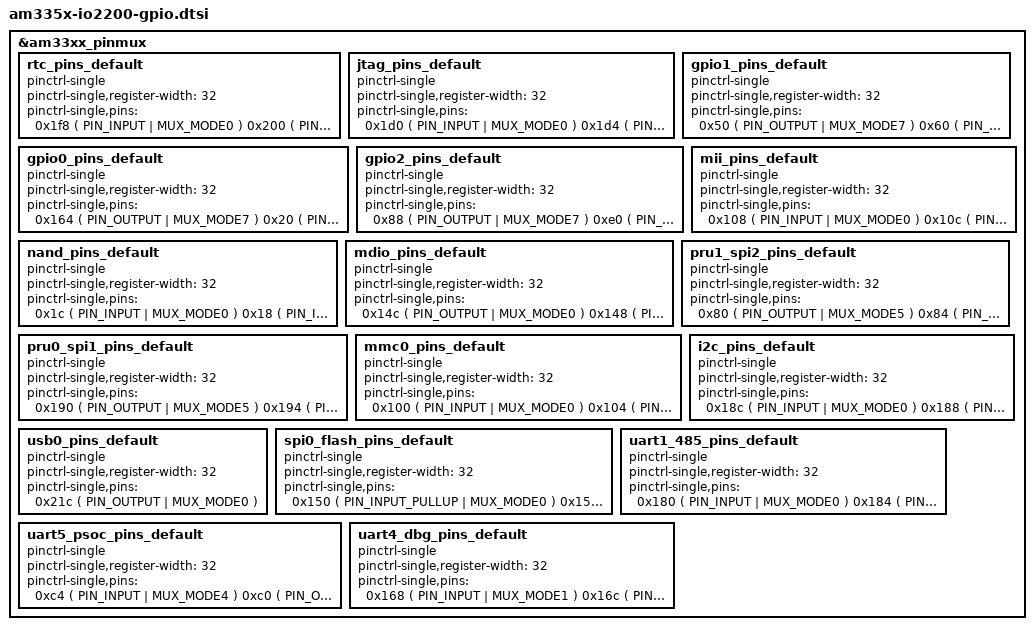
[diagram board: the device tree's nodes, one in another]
/* This file was auto-generated by TI PinMux on 10/19/2017 at 10:42:39 AM. */
/* This file should only be used as a reference.  Some pins/peripherals, */
/* depending on your use case, may need additional configuration. */

/* Some or all the pins from the following groups are not used by device tree 
   ddr
   32k765
   usb0
*/
&am33xx_pinmux {
rtc_pins_default: rtc_pins_default {
	compatible = "pinctrl-single";
	#pinctrl-cells = <1>;
	pinctrl-single,register-width = <32>;
	pinctrl-single,pins = <
		0x1f8 ( PIN_INPUT | MUX_MODE0 ) /* (B5) RTC_PORz.RTC_PORz */
		0x200 ( PIN_OUTPUT | MUX_MODE0 ) /* (C5) EXT_WAKEUP.EXT_WAKEUP */
		0x204 ( PIN_INPUT | MUX_MODE0 ) /* (B4) ENZ_KALDO_1P8V.ENZ_KALDO_1P8V */
	>;
};

jtag_pins_default: jtag_pins_default {
	compatible = "pinctrl-single";
	#pinctrl-cells = <1>;
	pinctrl-single,register-width = <32>;
	pinctrl-single,pins = <
		0x1d0 ( PIN_INPUT | MUX_MODE0 ) /* (C11) TMS.TMS */
		0x1d4 ( PIN_INPUT | MUX_MODE0 ) /* (B11) TDI.TDI */
		0x1d8 ( PIN_OUTPUT | MUX_MODE0 ) /* (A11) TDO.TDO */
		0x1dc ( PIN_INPUT | MUX_MODE0 ) /* (A12) TCK.TCK */
		0x1e0 ( PIN_INPUT | MUX_MODE0 ) /* (B10) nTRST.nTRST */
		0x1e4 ( PIN_INPUT | MUX_MODE0 ) /* (C14) EMU0.EMU0 */
		0x1e8 ( PIN_INPUT | MUX_MODE0 ) /* (B14) EMU1.EMU1 */
	>;
};

gpio1_pins_default: gpio1_pins_default {
	compatible = "pinctrl-single";
	#pinctrl-cells = <1>;
	pinctrl-single,register-width = <32>;
	pinctrl-single,pins = <
		0x50 ( PIN_OUTPUT | MUX_MODE7 ) /* (R14) gpmc_a4.gpio1[20] */
		0x60 ( PIN_OUTPUT | MUX_MODE7 ) /* (R14) gpmc_a8.gpio1[24] */
	>;
};

gpio0_pins_default: gpio0_pins_default {
	compatible = "pinctrl-single";
	#pinctrl-cells = <1>;
	pinctrl-single,register-width = <32>;
	pinctrl-single,pins = <
		0x164 ( PIN_OUTPUT | MUX_MODE7 ) /* (C18) eCAP0_in_PWM0_out.gpio0[7] */
		0x20 ( PIN_INPUT_PULLUP | MUX_MODE7 ) /* (U10) gpmc_ad8.gpio0[22] */
		0x24 ( PIN_INPUT_PULLDOWN | MUX_MODE7 ) /* (T10) gpmc_ad9.gpio0[23] */
		0x28 ( PIN_INPUT | MUX_MODE7 ) /* (T11) gpmc_ad10.gpio0[26] */
		0x2c ( PIN_INPUT | MUX_MODE7 ) /* (U12) gpmc_ad11.gpio0[27] */
		0x144 ( PIN_INPUT_PULLDOWN | MUX_MODE7 ) /* (H18) rmii1_refclk.gpio0[29] */
	>;
};

gpio2_pins_default: gpio2_pins_default {
	compatible = "pinctrl-single";
	#pinctrl-cells = <1>;
	pinctrl-single,register-width = <32>;
	pinctrl-single,pins = <
		0x88 ( PIN_OUTPUT | MUX_MODE7 ) /* (T13) gpmc_csn3.gpio2[0] */
		0xe0 ( PIN_OUTPUT | MUX_MODE7 ) /* (U5) lcd_vsync.gpio2[22] */
	>;
};

mii_pins_default: mii_pins_default {
	compatible = "pinctrl-single";
	#pinctrl-cells = <1>;
	pinctrl-single,register-width = <32>;
	pinctrl-single,pins = <
		0x108 ( PIN_INPUT | MUX_MODE0 ) /* (H16) gmii1_col.gmii1_col */
		0x10c ( PIN_INPUT | MUX_MODE0 ) /* (H17) gmii1_crs.gmii1_crs */
		0x110 ( PIN_INPUT_PULLDOWN | MUX_MODE0 ) /* (J15) gmii1_rxer.gmii1_rxer */
		0x114 ( PIN_OUTPUT | MUX_MODE0 ) /* (J16) gmii1_txen.gmii1_txen */
		0x118 ( PIN_INPUT | MUX_MODE0 ) /* (J17) gmii1_rxdv.gmii1_rxdv */
		0x12c ( PIN_INPUT | MUX_MODE0 ) /* (K18) gmii1_txclk.gmii1_txclk */
		0x130 ( PIN_INPUT | MUX_MODE0 ) /* (L18) gmii1_rxclk.gmii1_rxclk */
		0x128 ( PIN_OUTPUT | MUX_MODE0 ) /* (K17) gmii1_txd0.gmii1_txd0 */
		0x124 ( PIN_OUTPUT | MUX_MODE0 ) /* (K16) gmii1_txd1.gmii1_txd1 */
		0x120 ( PIN_OUTPUT | MUX_MODE0 ) /* (K15) gmii1_txd2.gmii1_txd2 */
		0x11c ( PIN_OUTPUT | MUX_MODE0 ) /* (J18) gmii1_txd3.gmii1_txd3 */
		0x140 ( PIN_INPUT | MUX_MODE0 ) /* (M16) gmii1_rxd0.gmii1_rxd0 */
		0x13c ( PIN_INPUT | MUX_MODE0 ) /* (L15) gmii1_rxd1.gmii1_rxd1 */
		0x138 ( PIN_INPUT | MUX_MODE0 ) /* (L16) gmii1_rxd2.gmii1_rxd2 */
		0x134 ( PIN_INPUT | MUX_MODE0 ) /* (L17) gmii1_rxd3.gmii1_rxd3 */
	>;
};

nand_pins_default: nand_pins_default {
	compatible = "pinctrl-single";
	#pinctrl-cells = <1>;
	pinctrl-single,register-width = <32>;
	pinctrl-single,pins = <
		0x1c ( PIN_INPUT | MUX_MODE0 ) /* (T9) gpmc_ad7.gpmc_ad7 */
		0x18 ( PIN_INPUT | MUX_MODE0 ) /* (R9) gpmc_ad6.gpmc_ad6 */
		0x14 ( PIN_INPUT | MUX_MODE0 ) /* (V8) gpmc_ad5.gpmc_ad5 */
		0x10 ( PIN_INPUT | MUX_MODE0 ) /* (U8) gpmc_ad4.gpmc_ad4 */
		0xc ( PIN_INPUT | MUX_MODE0 ) /* (T8) gpmc_ad3.gpmc_ad3 */
		0x8 ( PIN_INPUT | MUX_MODE0 ) /* (R8) gpmc_ad2.gpmc_ad2 */
		0x4 ( PIN_INPUT | MUX_MODE0 ) /* (V7) gpmc_ad1.gpmc_ad1 */
		0x0 ( PIN_INPUT | MUX_MODE0 ) /* (U7) gpmc_ad0.gpmc_ad0 */
		0x70 ( PIN_INPUT | MUX_MODE0 ) /* (T17) gpmc_wait0.gpmc_wait0 */
		0x74 ( PIN_OUTPUT | MUX_MODE0 ) /* (U17) gpmc_wpn.gpmc_wpn */
		0x90 ( PIN_OUTPUT | MUX_MODE0 ) /* (R7) gpmc_advn_ale.gpmc_advn_ale */
		0x94 ( PIN_OUTPUT | MUX_MODE0 ) /* (T7) gpmc_oen_ren.gpmc_oen_ren */
		0x98 ( PIN_OUTPUT | MUX_MODE0 ) /* (U6) gpmc_wen.gpmc_wen */
		0x9c ( PIN_OUTPUT | MUX_MODE0 ) /* (T6) gpmc_be0n_cle.gpmc_be0n_cle */
		0x7c ( PIN_OUTPUT | MUX_MODE0 ) /* (V6) gpmc_csn0.gpmc_csn0 */
	>;
};

mdio_pins_default: mdio_pins_default {
	compatible = "pinctrl-single";
	#pinctrl-cells = <1>;
	pinctrl-single,register-width = <32>;
	pinctrl-single,pins = <
		0x14c ( PIN_OUTPUT | MUX_MODE0 ) /* (M18) mdio_clk.mdio_clk */
		0x148 ( PIN_INPUT | MUX_MODE0 ) /* (M17) mdio_data.mdio_data */
	>;
};

pru1_spi2_pins_default: pru1_spi2_pins_default {
	compatible = "pinctrl-single";
	#pinctrl-cells = <1>;
	pinctrl-single,register-width = <32>;
	pinctrl-single,pins = <
		0x80 ( PIN_OUTPUT | MUX_MODE5 ) /* (U9) gpmc_csn1.pr1_pru1_pru_r30[12] */
		0x84 ( PIN_OUTPUT | MUX_MODE5 ) /* (V9) gpmc_csn2.pr1_pru1_pru_r30[13] */
		0x170 ( PIN_OUTPUT | MUX_MODE5 ) /* (E15) uart0_rxd.pr1_pru1_pru_r30[14] */
		0x174 ( PIN_INPUT | MUX_MODE6 ) /* (E16) uart0_txd.pr1_pru1_pru_r31[15] */
	>;
};

pru0_spi1_pins_default: pru0_spi1_pins_default {
	compatible = "pinctrl-single";
	#pinctrl-cells = <1>;
	pinctrl-single,register-width = <32>;
	pinctrl-single,pins = <
		0x190 ( PIN_OUTPUT | MUX_MODE5 ) /* (A13) mcasp0_aclkx.pr1_pru0_pru_r30[0] */
		0x194 ( PIN_OUTPUT | MUX_MODE5 ) /* (B13) mcasp0_fsx.pr1_pru0_pru_r30[1] */
		0x198 ( PIN_OUTPUT | MUX_MODE5 ) /* (D12) mcasp0_axr0.pr1_pru0_pru_r30[2] */
		0x19c ( PIN_OUTPUT | MUX_MODE5 ) /* (C12) mcasp0_ahclkr.pr1_pru0_pru_r30[3] */
		0x1a0 ( PIN_OUTPUT | MUX_MODE5 ) /* (B12) mcasp0_aclkr.pr1_pru0_pru_r30[4] */
		0x1a4 ( PIN_OUTPUT | MUX_MODE5 ) /* (C13) mcasp0_fsr.pr1_pru0_pru_r30[5] */
		0x1a8 ( PIN_OUTPUT | MUX_MODE5 ) /* (D13) mcasp0_axr1.pr1_pru0_pru_r30[6] */
		0x1ac ( PIN_OUTPUT | MUX_MODE5 ) /* (A14) mcasp0_ahclkx.pr1_pru0_pru_r30[7] */
		0x30 ( PIN_OUTPUT | MUX_MODE6 ) /* (T12) gpmc_ad12.pr1_pru0_pru_r30[14] */
		0x34 ( PIN_OUTPUT | MUX_MODE6 ) /* (R12) gpmc_ad13.pr1_pru0_pru_r30[15] */
		0x38 ( PIN_INPUT | MUX_MODE6 ) /* (V13) gpmc_ad14.pr1_pru0_pru_r31[14] */
		0x3c ( PIN_INPUT | MUX_MODE6 ) /* (U13) gpmc_ad15.pr1_pru0_pru_r31[15] */
		0x1b4 ( PIN_INPUT | MUX_MODE5 ) /* (D14) xdma_event_intr1.pr1_pru0_pru_r31[16] */
	>;
};

mmc0_pins_default: mmc0_pins_default {
	compatible = "pinctrl-single";
	#pinctrl-cells = <1>;
	pinctrl-single,register-width = <32>;
	pinctrl-single,pins = <
		0x100 ( PIN_INPUT | MUX_MODE0 ) /* (G17) mmc0_clk.mmc0_clk */
		0x104 ( PIN_INPUT | MUX_MODE0 ) /* (G18) mmc0_cmd.mmc0_cmd */
		0xfc ( PIN_INPUT | MUX_MODE0 ) /* (G16) mmc0_dat0.mmc0_dat0 */
		0xf8 ( PIN_INPUT | MUX_MODE0 ) /* (G15) mmc0_dat1.mmc0_dat1 */
		0xf4 ( PIN_INPUT | MUX_MODE0 ) /* (F18) mmc0_dat2.mmc0_dat2 */
		0xf0 ( PIN_INPUT | MUX_MODE0 ) /* (F17) mmc0_dat3.mmc0_dat3 */
		0x160 ( PIN_INPUT | MUX_MODE5 ) /* (C15) spi0_cs1.mmc0_sdcd */
	>;
};

i2c_pins_default: i2c_pins_default {
	compatible = "pinctrl-single";
	#pinctrl-cells = <1>;
	pinctrl-single,register-width = <32>;
	pinctrl-single,pins = <
		0x18c ( PIN_INPUT | MUX_MODE0 ) /* (C16) I2C0_SCL.I2C0_SCL */
		0x188 ( PIN_INPUT | MUX_MODE0 ) /* (C17) I2C0_SDA.I2C0_SDA */
	>;
};

usb0_pins_default: usb0_pins_default {
	compatible = "pinctrl-single";
	#pinctrl-cells = <1>;
	pinctrl-single,register-width = <32>;
	pinctrl-single,pins = <
		0x21c ( PIN_OUTPUT | MUX_MODE0 ) /* (F16) USB0_DRVVBUS.USB0_DRVVBUS */
	>;
};

spi0_flash_pins_default: spi0_flash_pins_default {
	compatible = "pinctrl-single";
	#pinctrl-cells = <1>;
	pinctrl-single,register-width = <32>;
	pinctrl-single,pins = <
		0x150 ( PIN_INPUT_PULLUP | MUX_MODE0 ) /* (A17) spi0_sclk.spi0_sclk */
		0x154 ( PIN_INPUT_PULLUP | MUX_MODE0 ) /* (B17) spi0_d0.spi0_d0 */
		0x158 ( PIN_INPUT_PULLUP | MUX_MODE0 ) /* (B16) spi0_d1.spi0_d1 */
		0x15c ( PIN_INPUT_PULLUP | MUX_MODE0 ) /* (A16) spi0_cs0.spi0_cs0 */
	>;
};

uart1_485_pins_default: uart1_485_pins_default {
	compatible = "pinctrl-single";
	#pinctrl-cells = <1>;
	pinctrl-single,register-width = <32>;
	pinctrl-single,pins = <
		0x180 ( PIN_INPUT | MUX_MODE0 ) /* (D16) uart1_rxd.uart1_rxd */
		0x184 ( PIN_OUTPUT | MUX_MODE0 ) /* (D15) uart1_txd.uart1_txd */
		0x17c ( PIN_OUTPUT | MUX_MODE0 ) /* (D17) uart1_rtsn.uart1_rtsn */
	>;
};

uart5_psoc_pins_default: uart5_psoc_pins_default {
	compatible = "pinctrl-single";
	#pinctrl-cells = <1>;
	pinctrl-single,register-width = <32>;
	pinctrl-single,pins = <
		0xc4 ( PIN_INPUT | MUX_MODE4 ) /* (U2) lcd_data9.uart5_rxd */
		0xc0 ( PIN_OUTPUT | MUX_MODE4 ) /* (U1) lcd_data8.uart5_txd */
	>;
};

uart4_dbg_pins_default: uart4_dbg_pins_default {
	compatible = "pinctrl-single";
	#pinctrl-cells = <1>;
	pinctrl-single,register-width = <32>;
	pinctrl-single,pins = <
		0x168 ( PIN_INPUT | MUX_MODE1 ) /* (E18) uart0_ctsn.uart4_rxd */
		0x16c ( PIN_OUTPUT | MUX_MODE1 ) /* (E17) uart0_rtsn.uart4_txd */
	>;
};
};

